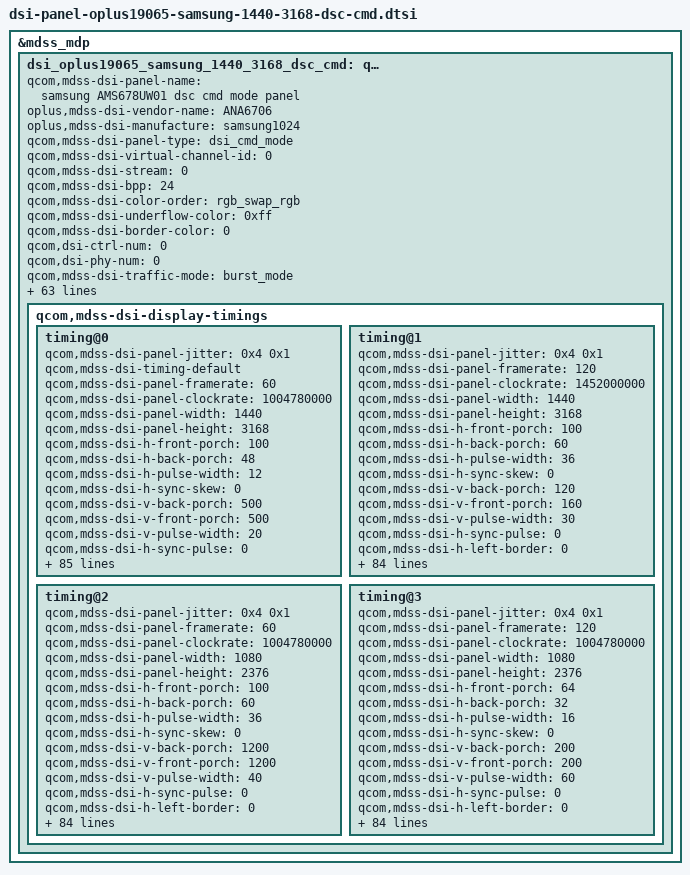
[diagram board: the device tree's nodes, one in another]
&mdss_mdp {
	dsi_oplus19065_samsung_1440_3168_dsc_cmd: qcom,mdss_dsi_oppo19065_samsung_1440_3168_dsc_cmd {
		qcom,mdss-dsi-panel-name = "samsung AMS678UW01 dsc cmd mode panel";
		oplus,mdss-dsi-vendor-name = "ANA6706";
		oplus,mdss-dsi-manufacture = "samsung1024";
		qcom,mdss-dsi-panel-type = "dsi_cmd_mode";
		qcom,mdss-dsi-virtual-channel-id = <0>;
		qcom,mdss-dsi-stream = <0>;
		qcom,mdss-dsi-bpp = <24>;
		qcom,mdss-dsi-color-order = "rgb_swap_rgb";
		qcom,mdss-dsi-underflow-color = <0xff>;
		qcom,mdss-dsi-border-color = <0>;
		qcom,dsi-ctrl-num = <0>;
		qcom,dsi-phy-num = <0>;
		qcom,mdss-dsi-traffic-mode = "burst_mode";
		qcom,mdss-dsi-lane-map = "lane_map_0123";
		qcom,mdss-dsi-bllp-eof-power-mode;
		qcom,mdss-dsi-bllp-power-mode;
		qcom,mdss-dsi-lane-0-state;
		qcom,mdss-dsi-lane-1-state;
		qcom,mdss-dsi-lane-2-state;
		qcom,mdss-dsi-lane-3-state;
		qcom,mdss-dsi-dma-trigger = "trigger_sw";
		qcom,mdss-dsi-mdp-trigger = "none";
		qcom,mdss-dsi-reset-sequence = <1 10>, <0 2>, <1 10>;
		qcom,mdss-dsi-te-pin-select = <1>;
		qcom,mdss-dsi-te-dcs-command = <1>;
		qcom,mdss-pan-physical-width-dimension = <71>;
		qcom,mdss-pan-physical-height-dimension = <157>;
		qcom,mdss-dsi-init-delay-us = <1000>;
		qcom,mdss-dsi-te-check-enable;
		qcom,mdss-dsi-te-using-te-pin;
		qcom,mdss-dsi-lp11-init;
		qcom,mdss-dsi-wr-mem-start = <0x2c>;
		qcom,mdss-dsi-wr-mem-continue = <0x3c>;
		/* HDR Setting */
		qcom,mdss-dsi-panel-hdr-enabled;
		qcom,mdss-dsi-panel-hdr-color-primaries = <15635 16450 34000 16000 13250 34500 7500 3000>;
		qcom,mdss-dsi-panel-peak-brightness = <5400000>;
		qcom,mdss-dsi-panel-average-brightness = <2000000>;
		qcom,mdss-dsi-panel-blackness-level = <2000>;

		qcom,esd-check-enabled;
		qcom,mdss-dsi-panel-status-check-mode = "reg_read";
		qcom,mdss-dsi-panel-status-command = [
						06 01 00 01 05 00 02 E9 00
						06 01 00 01 05 00 02 EE 00
						06 01 00 01 05 00 02 0A 00
						];
		qcom,mdss-dsi-panel-status-command-state = "dsi_hs_mode";
		qcom,mdss-dsi-panel-status-value = <0x00 0x00 0x00 0x00 0x00 0x9C>;
		qcom,mdss-dsi-panel-status-read-length = <4 1 1>;

		qcom,dynamic-mode-switch-enabled;
		qcom,dynamic-mode-switch-type = "dynamic-resolution-switch-immediate";
		qcom,mdss-dsi-display-timings {
			timing@0{
				qcom,mdss-dsi-panel-jitter = <0x4 0x1>;
				qcom,mdss-dsi-timing-default;
				qcom,mdss-dsi-panel-framerate = <60>;
				qcom,mdss-dsi-panel-clockrate = <1004780000>;
				qcom,mdss-dsi-panel-width = <1440>;
				qcom,mdss-dsi-panel-height = <3168>;

				qcom,mdss-dsi-h-front-porch = <100>;
				qcom,mdss-dsi-h-back-porch = <48>;
				qcom,mdss-dsi-h-pulse-width = <12>;
				qcom,mdss-dsi-h-sync-skew = <0>;
				qcom,mdss-dsi-v-back-porch = <500>;
				qcom,mdss-dsi-v-front-porch = <500>;
				qcom,mdss-dsi-v-pulse-width = <20>;
				qcom,mdss-dsi-h-sync-pulse = <0>;

				qcom,mdss-dsi-h-left-border = <0>;
				qcom,mdss-dsi-h-right-border = <0>;
				qcom,mdss-dsi-v-top-border = <0>;
				qcom,mdss-dsi-v-bottom-border = <0>;

				qcom,dsi-select-clocks = "mux_byte_clk0", "mux_pixel_clk0","pw_bb_clk2";

				oplus,fod-on-vblank = <1>;
				oplus,fod-off-vblank = <0>;
				qcom,mdss-dsi-panel-read-register-open-command = [
					39 01 00 00 00 00 03 F0 5A 5A
					];
				qcom,mdss-dsi-panel-id1-command = [
					06 01 00 00 00 00 01 E9
					];
				qcom,mdss-dsi-panel-read-register-close-command = [
					39 01 00 00 00 00 03 F0 A5 A5
					];
				qcom,mdss-dsi-timing-switch-command = [
					39 01 00 00 00 00 03 F0 5A 5A
					39 01 00 00 00 00 05 2A 00 00 05 9F 		/* CASET */
					39 01 00 00 00 00 05 2B 00 00 0C 5F 		/* PASET */
					15 01 00 00 00 00 02 60 00					/* 60HZ */
					15 01 00 00 00 00 02 F7 0F
					15 01 00 00 00 00 02 BA 03
					39 01 00 00 07 00 03 F0 A5 A5
				];
				qcom,mdss-dsi-on-command = [
					/* Sleep Out(11h) */
					05 01 00 00 0B 00 01 11
					/* SP Error improvement Setting*/
					39 01 00 00 00 00 03 F0 5A 5A
					15 01 00 00 00 00 02 B0 4F
					39 01 00 00 00 00 03 F5 5C 78
					15 01 00 00 00 00 02 B0 07
					15 01 00 00 00 00 02 C0 68
					39 01 00 00 00 00 03 F0 A5 A5
					/* color dot improment */
					39 01 00 00 00 00 03 F0 5A 5A
					15 01 00 00 00 00 02 B0 22
					15 01 00 00 00 00 02 F5 65
					15 01 00 00 00 00 02 B0 38
					15 01 00 00 00 00 02 F5 0F
					15 01 00 00 00 00 02 B0 56
					15 01 00 00 00 00 02 F5 C4
					39 01 00 00 00 00 03 F0 A5 A5
					/* Green Line improvement Setting */
					39 01 00 00 00 00 03 F0 5A 5A
					15 01 00 00 00 00 02 B0 03
					39 01 00 00 00 00 03 CB FF FF
					15 01 00 00 00 00 02 F7 0F
					39 01 00 00 0B 00 03 F0 A5 A5
					/* DSC Setting */
					07 01 00 00 00 00 01 01
					/* DSC enable */
					39 01 00 00 00 00 59 9E
					11 00 00 AB 30 A0 0C 60
					05 A0 00 10 02 D0 03 84
					01 9A 02 68 00 19 01 d1
					00 0E 00 09 04 cd 05 d6
					16 00 10 EC 07 10 20 00
					06 0F 0F 33 0E 1C 2A 38
					46 54 62 69 70 77 79 7B
					7D 7E 02 02 22 00 2A 40
					32 BE 3A FC 3A FA 3A F8
					3B 38 3B 78 3B 76 4B B6
					4B B4 4B F4 5B F4 7C 34
					39 01 00 00 00 00 03 F0 5A 5A
					15 01 00 00 00 00 02 F7 0F
					39 01 00 00 00 00 03 F0 A5 A5
					/* Common Setting */
					15 01 00 00 00 00 02 35 00					/* TE On(Vsync) */
					/* CASET/PASET Setting */
					39 01 00 00 00 00 05 2A 00 00 05 9F 		/* CASET */
					39 01 00 00 00 00 05 2B 00 00 0C 5F 		/* PASET */
					/* TSP SYNC Setting */
					39 01 00 00 00 00 03 F0 5A 5A
					15 01 00 00 00 00 02 B0 05
					39 01 00 00 00 00 05 B9 07 02 40 23 		/* SYNC ENABLE */
					39 01 00 00 00 00 03 F0 A5 A5
					/* FD Setting On */
					39 01 00 00 00 00 03 F0 5A 5A
					15 01 00 00 00 00 02 B0 54
					15 01 00 00 00 00 02 B5 48
					39 01 00 00 6F 00 03 F0 A5 A5
					/* Brightness Control */
					39 01 00 00 00 00 03 F0 5A 5A				/* Dimming Setting */
					15 01 00 00 00 00 02 B0 0B
					15 01 00 00 00 00 02 B1 01					/* Dimming Speed Setting : 0x01 : 1Frame*/
					15 01 00 00 00 00 02 B0 02
					15 01 00 00 00 00 02 B5 13					/* 0x13 : ELVSS DIM OFF */
					15 01 00 00 00 00 02 53 28
					39 01 00 00 00 00 03 F0 A5 A5
					/* 60Hz */
					39 01 00 00 00 00 03 F0 5A 5A
					15 01 00 00 00 00 02 60 00					/*60HZ*/
					15 01 00 00 00 00 02 F7 0F
					15 01 00 00 00 00 02 BA 03
					39 01 00 00 00 00 03 F0 A5 A5
				];
				qcom,mdss-dsi-post-on-backlight = [
					/* Display On */
					39 01 00 00 00 00 03 9F 5A 5A
					05 01 00 00 00 00 01 29
					05 01 00 00 00 00 01 13
					39 01 00 00 00 00 03 9F A5 A5
				];
				qcom,mdss-dsi-off-command=[
					05 01 00 00 0A 00 02 28 00
					05 01 00 00 78 00 02 10 00
				];
				qcom,mdss-dsi-lp1-command = [
					/* SEED CRC OFF */
					15 01 00 00 00 00 02 82 00
					/* Aod Mode */
					39 01 00 00 00 00 03 F0 5A 5A
					15 01 00 00 00 00 02 B0 06
					15 01 00 00 00 00 02 F4 8A
					15 01 00 00 00 00 02 BB 29
					15 01 00 00 00 00 02 6A 00
					15 01 00 00 00 00 02 53 22
					39 01 00 00 14 00 03 F0 A5 A5
				];
				qcom,mdss-dsi-nolp-command = [
					39 01 00 00 00 00 03 F0 5A 5A
					15 00 00 00 00 00 02 60 00 /*60HZ*/
					15 00 00 00 00 00 02 F7 0F
					39 01 00 00 00 00 03 F0 A5 A5
					/* Normal Mode */
					39 01 00 00 00 00 03 F0 5A 5A
					15 01 00 00 00 00 02 6A 00
					15 01 00 00 00 00 02 53 28
					39 01 00 00 00 00 03 F0 A5 A5
				];
				qcom,mdss-dsi-aod-hbm-on-command = [
					/* HBM Mode ON */
					39 01 00 00 00 00 02 53 E0
					/* 0xE0 Normal transition */
					39 01 00 00 00 00 03 51 05 93
				];
				qcom,mdss-dsi-aod-hbm-off-command = [
					15 01 00 00 00 00 02 53 22
					39 01 00 00 00 00 03 51 00 01
				];
				qcom,mdss-dsi-hbm-on-command = [
					15 01 00 00 00 00 02 53 E0
					39 01 00 00 22 00 03 51 05 93
				];
				qcom,mdss-dsi-normal-hbm-on-command = [
					15 01 00 00 00 00 02 53 E0
					39 01 00 00 00 00 03 51 07 FF
				];
				qcom,mdss-dsi-aod-high-mode-command = [
					/* AOD 50nit */
					15 01 00 00 00 00 02 53 22
				];
				qcom,mdss-dsi-aod-low-mode-command = [
					/* AOD 10nit */
					15 01 00 00 00 00 02 53 23
				];
				qcom,mdss-dsi-seed-off-command = [
					/* TCS OFF */
					39 01 00 00 00 00 03 F0 5A 5A
					15 01 00 00 00 00 02 84 00
					39 01 00 00 00 00 03 F0 A5 A5
					/* CRC OFF */
					39 01 00 00 00 00 03 F0 5A 5A
					15 01 00 00 00 00 02 B8 01
					39 01 00 00 00 00 03 F0 A5 A5
				];
				qcom,mdss-dsi-seed-0-command = [
					39 01 00 00 00 00 03 F0 5A 5A
					15 01 00 00 00 00 02 B0 0C
					15 01 00 00 00 00 02 92 07
					39 01 00 00 00 00 03 F0 A5 A5
				];
				qcom,mdss-dsi-seed-1-command = [
					39 01 00 00 00 00 03 F0 5A 5A
					15 01 00 00 00 00 02 B0 0C
					15 01 00 00 00 00 02 92 27
					39 01 00 00 00 00 03 F0 A5 A5
				];
				qcom,mdss-dsi-seed-2-command = [
					39 01 00 00 00 00 03 F0 5A 5A
					15 01 00 00 00 00 02 B0 0C
					15 01 00 00 00 00 02 92 07
					39 01 00 00 00 00 03 F0 A5 A5
				];
				qcom,mdss-dsi-mca-on-command = [
					/* MCA ON */
					39 01 00 00 00 00 03 F0 5A 5A
					15 01 00 00 00 00 02 B0 06
					15 01 00 00 00 00 02 97 01
					15 01 00 00 00 00 02 B0 04
					15 01 00 00 00 00 02 98 01
					39 01 00 00 00 00 03 F0 A5 A5
				];
				qcom,mdss-dsi-mca-off-command = [
					/* MCA OFF */
					39 01 00 00 00 00 03 F0 5A 5A
					15 01 00 00 00 00 02 B0 06
					15 01 00 00 00 00 02 97 00
					15 01 00 00 00 00 02 B0 04
					15 01 00 00 00 00 02 98 00
					39 01 00 00 00 00 03 F0 A5 A5
				];
				qcom,mdss-dsi-aod-hbm-on-command-state = "dsi_hs_mode";
				qcom,mdss-dsi-aod-hbm-off-command-state = "dsi_hs_mode";
				qcom,mdss-dsi-timing-switch-command-state = "dsi_hs_mode";
				qcom,mdss-dsi-on-command-state = "dsi_lp_mode";
				qcom,mdss-dsi-off-command-state = "dsi_hs_mode";
				qcom,mdss-dsi-seed-off-command-state = "dsi_hs_mode";
				qcom,mdss-dsi-seed-0-command-state = "dsi_hs_mode";
				qcom,mdss-dsi-seed-1-command-state = "dsi_hs_mode";
				qcom,mdss-dsi-seed-2-command-state = "dsi_hs_mode";

				qcom,compression-mode = "dsc";
				qcom,lm-split = <720 720>;
				qcom,mdss-dsc-encoders = <2>;
				qcom,mdss-dsc-slice-height = <16>;
				qcom,mdss-dsc-slice-width = <720>;
				qcom,mdss-dsc-slice-per-pkt = <2>;
				qcom,mdss-dsc-bit-per-component = <10>;
				qcom,mdss-dsc-bit-per-pixel = <10>;
				qcom,mdss-dsc-block-prediction-enable;
				qcom,mdss-dsi-panel-id1-command-state = "dsi_lp_mode";
				qcom,mdss-dsi-panel-read-register-open-state = "dsi_lp_mode";
				qcom,mdss-dsi-panel-read-register-close-state = "dsi_lp_mode";
			};
			timing@1 {
				qcom,mdss-dsi-panel-jitter = <0x4 0x1>;
				qcom,mdss-dsi-panel-framerate = <120>;
				qcom,mdss-dsi-panel-clockrate = <1452000000>;
				qcom,mdss-dsi-panel-width = <1440>;
				qcom,mdss-dsi-panel-height = <3168>;

				qcom,mdss-dsi-h-front-porch = <100>;
				qcom,mdss-dsi-h-back-porch = <60>;
				qcom,mdss-dsi-h-pulse-width = <36>;
				qcom,mdss-dsi-h-sync-skew = <0>;
				qcom,mdss-dsi-v-back-porch = <120>;
				qcom,mdss-dsi-v-front-porch = <160>;
				qcom,mdss-dsi-v-pulse-width = <30>;
				qcom,mdss-dsi-h-sync-pulse = <0>;
				qcom,mdss-dsi-h-left-border = <0>;
				qcom,mdss-dsi-h-right-border = <0>;
				qcom,mdss-dsi-v-top-border = <0>;
				qcom,mdss-dsi-v-bottom-border = <0>;

				qcom,dsi-select-clocks = "mux_byte_clk0", "mux_pixel_clk0","pw_bb_clk2";

				oplus,fod-on-vblank = <2>;
				oplus,fod-off-vblank = <0>;

				qcom,mdss-dsi-panel-read-register-open-command = [
					39 01 00 00 00 00 03 F0 5A 5A
					];
				qcom,mdss-dsi-panel-id1-command = [
					06 01 00 00 00 00 01 E9
					];
				qcom,mdss-dsi-panel-read-register-close-command = [
					39 01 00 00 00 00 03 F0 A5 A5
					];
				qcom,mdss-dsi-timing-switch-command = [
					39 01 00 00 00 00 03 F0 5A 5A
					39 01 00 00 00 00 05 2A 00 00 05 9F 		/* CASET */
					39 01 00 00 00 00 05 2B 00 00 0C 5F 		/* PASET */
					15 01 00 00 00 00 02 60 20					/* 120HZ */
					15 01 00 00 00 00 02 F7 0F
					15 01 00 00 00 00 02 BA 03
					39 01 00 00 07 00 03 F0 A5 A5
				];
				qcom,mdss-dsi-on-command = [
					/* Sleep Out(11h) */
					05 01 00 00 0B 00 01 11
					/* SP Error improvement Setting*/
					39 01 00 00 00 00 03 F0 5A 5A
					15 01 00 00 00 00 02 B0 4F
					39 01 00 00 00 00 03 F5 5C 78
					15 01 00 00 00 00 02 B0 07
					15 01 00 00 00 00 02 C0 68
					39 01 00 00 00 00 03 F0 A5 A5
					/* color dot improment */
					39 01 00 00 00 00 03 F0 5A 5A
					15 01 00 00 00 00 02 B0 22
					15 01 00 00 00 00 02 F5 65
					15 01 00 00 00 00 02 B0 38
					15 01 00 00 00 00 02 F5 0F
					15 01 00 00 00 00 02 B0 56
					15 01 00 00 00 00 02 F5 C4
					39 01 00 00 00 00 03 F0 A5 A5
					/* Green Line improvement Setting */
					39 01 00 00 00 00 03 F0 5A 5A
					15 01 00 00 00 00 02 B0 03
					39 01 00 00 00 00 03 CB FF FF
					15 01 00 00 00 00 02 F7 0F
					39 01 00 00 0B 00 03 F0 A5 A5
					/* DSC Setting */
					07 01 00 00 00 00 01 01
					/* DSC enable */
					39 01 00 00 00 00 59 9E
					12 00 00 AB 30 80 0C 60
					05 A0 00 60 02 D0 02 D0
					02 00 02 C2 00 20 09 62
					00 0A 00 0F 01 44 00 CC
					18 00 10 F0 07 10 20 00
					06 0F 0F 33 0E 1C 2A 38
					46 54 62 69 70 77 79 7B
					7D 7E 02 02 22 00 2A 40
					2A BE 3A FC 3A FA 3A F8
					3B 38 3B 78 3B B6 4B B6
					4B F4 4B F4 6C 34 84 74
					39 01 00 00 00 00 03 F0 5A 5A
					15 01 00 00 00 00 02 F7 0F
					39 01 00 00 00 00 03 F0 A5 A5
					/* Common Setting */
					15 01 00 00 00 00 02 35 00					/* TE On(Vsync) */
					/* CASET/PASET Setting */
					39 01 00 00 00 00 05 2A 00 00 05 9F 		/* CASET */
					39 01 00 00 00 00 05 2B 00 00 0C 5F 		/* PASET */
					/* TSP SYNC Setting */
					39 01 00 00 00 00 03 F0 5A 5A
					15 01 00 00 00 00 02 B0 05
					39 01 00 00 00 00 05 B9 07 02 40 23 		/* SYNC ENABLE */
					39 01 00 00 00 00 03 F0 A5 A5
					/* FD Setting On */
					39 01 00 00 00 00 03 F0 5A 5A
					15 01 00 00 00 00 02 B0 54
					15 01 00 00 00 00 02 B5 48
					39 01 00 00 6F 00 03 F0 A5 A5
					/* Brightness Control */
					39 01 00 00 00 00 03 F0 5A 5A				/* Dimming Setting */
					15 01 00 00 00 00 02 B0 0B
					15 01 00 00 00 00 02 B1 01					/* Dimming Speed Setting : 0x01 : 1Frame*/
					15 01 00 00 00 00 02 B0 02
					15 01 00 00 00 00 02 B5 13					/* 0x13 : ELVSS DIM OFF */
					15 01 00 00 00 00 02 53 28
					39 01 00 00 00 00 03 F0 A5 A5
					/* 120HZ */
					39 01 00 00 00 00 03 F0 5A 5A
					15 01 00 00 00 00 02 60 20					/* 120HZ */
					15 01 00 00 00 00 02 F7 0F
					15 01 00 00 00 00 02 BA 03
					39 01 00 00 00 00 03 F0 A5 A5
				];
				qcom,mdss-dsi-post-on-backlight = [
					/* Display On */
					39 01 00 00 00 00 03 9F 5A 5A
					05 01 00 00 00 00 01 29
					05 01 00 00 00 00 01 13
					39 01 00 00 00 00 03 9F A5 A5
				];
				qcom,mdss-dsi-off-command=[
					05 01 00 00 0A 00 02 28 00
					05 01 00 00 78 00 02 10 00
				];
				qcom,mdss-dsi-lp1-command = [
					/* SEED CRC OFF */
					15 01 00 00 00 00 02 82 00
					/* Aod Mode */
					39 01 00 00 00 00 03 F0 5A 5A
					15 01 00 00 00 00 02 B0 06
					15 01 00 00 00 00 02 F4 8A
					15 01 00 00 00 00 02 BB 29
					15 01 00 00 00 00 02 6A 00
					15 01 00 00 00 00 02 53 22
					39 01 00 00 14 00 03 F0 A5 A5
				];
				qcom,mdss-dsi-nolp-command = [
					39 01 00 00 00 00 03 F0 5A 5A
					15 00 00 00 00 00 02 60 20 /*120HZ*/
					15 00 00 00 00 00 02 F7 0F
					39 01 00 00 00 00 03 F0 A5 A5
					/* Normal Mode */
					39 01 00 00 00 00 03 F0 5A 5A
					15 01 00 00 00 00 02 6A 00
					15 01 00 00 00 00 02 53 28
					39 01 00 00 00 00 03 F0 A5 A5
				];
				qcom,mdss-dsi-aod-hbm-on-command = [
					/* HBM Mode ON */
					39 01 00 00 00 00 02 53 E0
					/* 0xE0 Normal transition */
					39 01 00 00 00 00 03 51 05 93
				];
				qcom,mdss-dsi-aod-hbm-off-command = [
					15 01 00 00 00 00 02 53 22
					39 01 00 00 00 00 03 51 00 01
				];
				qcom,mdss-dsi-hbm-on-command = [
					15 01 00 00 00 00 02 53 E0
					39 01 00 00 22 00 03 51 05 93
				];
				qcom,mdss-dsi-normal-hbm-on-command = [
					15 01 00 00 00 00 02 53 E0
					39 01 00 00 00 00 03 51 07 FF
				];
				qcom,mdss-dsi-aod-high-mode-command = [
					/* AOD 50nit */
					15 01 00 00 00 00 02 53 22
				];
				qcom,mdss-dsi-aod-low-mode-command = [
					/* AOD 10nit */
					15 01 00 00 00 00 02 53 23
				];
				qcom,mdss-dsi-seed-off-command = [
					/* TCS OFF */
					39 01 00 00 00 00 03 F0 5A 5A
					15 01 00 00 00 00 02 84 00
					39 01 00 00 00 00 03 F0 A5 A5
					/* CRC OFF */
					39 01 00 00 00 00 03 F0 5A 5A
					15 01 00 00 00 00 02 B8 01
					39 01 00 00 00 00 03 F0 A5 A5
				];
				qcom,mdss-dsi-seed-0-command = [
					39 01 00 00 00 00 03 F0 5A 5A
					15 01 00 00 00 00 02 B0 0C
					15 01 00 00 00 00 02 92 07
					39 01 00 00 00 00 03 F0 A5 A5
				];
				qcom,mdss-dsi-seed-1-command = [
					39 01 00 00 00 00 03 F0 5A 5A
					15 01 00 00 00 00 02 B0 0C
					15 01 00 00 00 00 02 92 27
					39 01 00 00 00 00 03 F0 A5 A5
				];
				qcom,mdss-dsi-seed-2-command = [
					39 01 00 00 00 00 03 F0 5A 5A
					15 01 00 00 00 00 02 B0 0C
					15 01 00 00 00 00 02 92 07
					39 01 00 00 00 00 03 F0 A5 A5
				];
				qcom,mdss-dsi-mca-on-command = [
					/* MCA ON */
					39 01 00 00 00 00 03 F0 5A 5A
					15 01 00 00 00 00 02 B0 06
					15 01 00 00 00 00 02 97 01
					15 01 00 00 00 00 02 B0 04
					15 01 00 00 00 00 02 98 01
					39 01 00 00 00 00 03 F0 A5 A5
				];
				qcom,mdss-dsi-mca-off-command = [
					/* MCA OFF */
					39 01 00 00 00 00 03 F0 5A 5A
					15 01 00 00 00 00 02 B0 06
					15 01 00 00 00 00 02 97 00
					15 01 00 00 00 00 02 B0 04
					15 01 00 00 00 00 02 98 00
					39 01 00 00 00 00 03 F0 A5 A5
				];
				qcom,mdss-dsi-aod-hbm-on-command-state = "dsi_hs_mode";
				qcom,mdss-dsi-aod-hbm-off-command-state = "dsi_hs_mode";
				qcom,mdss-dsi-timing-switch-command-state = "dsi_hs_mode";
				qcom,mdss-dsi-on-command-state = "dsi_lp_mode";
				qcom,mdss-dsi-off-command-state = "dsi_hs_mode";
				qcom,mdss-dsi-seed-off-command-state = "dsi_hs_mode";
				qcom,mdss-dsi-seed-0-command-state = "dsi_hs_mode";
				qcom,mdss-dsi-seed-1-command-state = "dsi_hs_mode";
				qcom,mdss-dsi-seed-2-command-state = "dsi_hs_mode";

				qcom,compression-mode = "dsc";
				qcom,lm-split = <720 720>;
				qcom,mdss-dsc-encoders = <2>;
				qcom,mdss-dsc-slice-height = <96>;
				qcom,mdss-dsc-slice-width = <720>;
				qcom,mdss-dsc-slice-per-pkt = <2>;
				qcom,mdss-dsc-bit-per-component = <10>;
				qcom,mdss-dsc-bit-per-pixel = <8>;
				qcom,mdss-dsc-block-prediction-enable;
				qcom,mdss-dsi-panel-id1-command-state = "dsi_lp_mode";
				qcom,mdss-dsi-panel-read-register-open-state = "dsi_lp_mode";
				qcom,mdss-dsi-panel-read-register-close-state = "dsi_lp_mode";
			};
			timing@2 {
				qcom,mdss-dsi-panel-jitter = <0x4 0x1>;
				qcom,mdss-dsi-panel-framerate = <60>;
				qcom,mdss-dsi-panel-clockrate = <1004780000>;
				qcom,mdss-dsi-panel-width = <1080>;
				qcom,mdss-dsi-panel-height = <2376>;

				qcom,mdss-dsi-h-front-porch = <100>;
				qcom,mdss-dsi-h-back-porch = <60>;
				qcom,mdss-dsi-h-pulse-width = <36>;
				qcom,mdss-dsi-h-sync-skew = <0>;
				qcom,mdss-dsi-v-back-porch = <1200>;
				qcom,mdss-dsi-v-front-porch = <1200>;
				qcom,mdss-dsi-v-pulse-width = <40>;
				qcom,mdss-dsi-h-sync-pulse = <0>;
				qcom,mdss-dsi-h-left-border = <0>;
				qcom,mdss-dsi-h-right-border = <0>;
				qcom,mdss-dsi-v-top-border = <0>;
				qcom,mdss-dsi-v-bottom-border = <0>;

				qcom,dsi-select-clocks = "mux_byte_clk0", "mux_pixel_clk0","pw_bb_clk2";

				oplus,fod-on-vblank = <1>;
				oplus,fod-off-vblank = <0>;

				qcom,mdss-dsi-panel-read-register-open-command = [
					39 01 00 00 00 00 03 F0 5A 5A
					];
				qcom,mdss-dsi-panel-id1-command = [
					06 01 00 00 00 00 01 E9
					];
				qcom,mdss-dsi-panel-read-register-close-command = [
					39 01 00 00 00 00 03 F0 A5 A5
					];
				qcom,mdss-dsi-timing-switch-command = [
					39 01 00 00 00 00 03 F0 5A 5A
					39 01 00 00 00 00 05 2A 00 00 04 37			/* CASET */
					39 01 00 00 00 00 05 2B 00 00 09 47			/* PASET */
					15 01 00 00 00 00 02 60 02					/* 60HZ */
					15 01 00 00 00 00 02 F7 0F
					15 01 00 00 00 00 02 BA 02
					39 01 00 00 07 00 03 F0 A5 A5
				];
				qcom,mdss-dsi-on-command = [
					/* Sleep Out(11h) */
					05 01 00 00 0B 00 01 11
					/* SP Error improvement Setting*/
					39 01 00 00 00 00 03 F0 5A 5A
					15 01 00 00 00 00 02 B0 4F
					39 01 00 00 00 00 03 F5 5C 78
					15 01 00 00 00 00 02 B0 07
					15 01 00 00 00 00 02 C0 68
					39 01 00 00 00 00 03 F0 A5 A5
					/* color dot improment */
					39 01 00 00 00 00 03 F0 5A 5A
					15 01 00 00 00 00 02 B0 22
					15 01 00 00 00 00 02 F5 65
					15 01 00 00 00 00 02 B0 38
					15 01 00 00 00 00 02 F5 0F
					15 01 00 00 00 00 02 B0 56
					15 01 00 00 00 00 02 F5 C4
					39 01 00 00 00 00 03 F0 A5 A5
					/* Green Line improvement Setting */
					39 01 00 00 00 00 03 F0 5A 5A
					15 01 00 00 00 00 02 B0 03
					39 01 00 00 00 00 03 CB FF FF
					15 01 00 00 00 00 02 F7 0F
					39 01 00 00 0B 00 03 F0 A5 A5
					/* DSC Setting */
					07 01 00 00 00 00 01 01
					/* DSC enable */
					39 01 00 00 00 00 59 9E
					11 00 00 89 30 80 09 48
					04 38 00 48 02 1C 02 1C
					02 00 02 52 00 20 06 3B
					00 07 00 0F 01 B1 01 6A
					18 00 10 F0 03 0C 20 00
					06 0B 0B 33 0E 1C 2A 38
					46 54 62 69 70 77 79 7B
					7D 7E 01 02 01 00 09 40
					09 BE 19 FC 19 FA 19 F8
					1A 38 1A 78 1A B6 2A B6
					2A F4 2A F4 4B 34 63 74
					39 01 00 00 00 00 03 F0 5A 5A
					15 01 00 00 00 00 02 F7 0F
					39 01 00 00 00 00 03 F0 A5 A5
					/* Common Setting */
					15 01 00 00 00 00 02 35 00					/* TE On(Vsync) */
					/* CASET/PASET Setting */
					39 01 00 00 00 00 05 2A 00 00 04 37			/* CASET */
					39 01 00 00 00 00 05 2B 00 00 09 47			/* PASET */
					/* TSP SYNC Setting */
					39 01 00 00 00 00 03 F0 5A 5A
					15 01 00 00 00 00 02 B0 05
					39 01 00 00 00 00 05 B9 07 02 40 23			/* SYNC ENABLE */
					39 01 00 00 00 00 03 F0 A5 A5
					/* FD Setting On */
					39 01 00 00 00 00 03 F0 5A 5A
					15 01 00 00 00 00 02 B0 54
					15 01 00 00 00 00 02 B5 48
					39 01 00 00 6F 00 03 F0 A5 A5
					/* Brightness Control */
					39 01 00 00 00 00 03 F0 5A 5A				/* Dimming Setting */
					15 01 00 00 00 00 02 B0 0B
					15 01 00 00 00 00 02 B1 01					/* Dimming Speed Setting : 0x01 : 1Frame*/
					15 01 00 00 00 00 02 B0 02
					15 01 00 00 00 00 02 B5 13					/* 0x13 : ELVSS DIM OFF */
					15 01 00 00 00 00 02 53 28
					39 01 00 00 00 00 03 F0 A5 A5
					/* 60HZ */
					39 01 00 00 00 00 03 F0 5A 5A
					15 01 00 00 00 00 02 60 02					/* 60HZ */
					15 01 00 00 00 00 02 F7 0F
					15 01 00 00 00 00 02 BA 02
					39 01 00 00 00 00 03 F0 A5 A5
				];
				qcom,mdss-dsi-post-on-backlight = [
					/* Display On */
					39 01 00 00 00 00 03 9F 5A 5A
					05 01 00 00 00 00 01 29
					05 01 00 00 00 00 01 13
					39 01 00 00 00 00 03 9F A5 A5
				];
				qcom,mdss-dsi-off-command=[
					05 01 00 00 0A 00 02 28 00
					05 01 00 00 78 00 02 10 00
				];
				qcom,mdss-dsi-lp1-command = [
					/* SEED CRC OFF */
					15 01 00 00 00 00 02 82 00
					/* Aod Mode */
					39 01 00 00 00 00 03 F0 5A 5A
					15 01 00 00 00 00 02 B0 06
					15 01 00 00 00 00 02 F4 8A
					15 01 00 00 00 00 02 BB 29
					15 01 00 00 00 00 02 6A 00
					15 01 00 00 00 00 02 53 22
					39 01 00 00 14 00 03 F0 A5 A5
				];
				qcom,mdss-dsi-nolp-command = [
					39 01 00 00 00 00 03 F0 5A 5A
					15 00 00 00 00 00 02 60 02 /*60HZ*/
					15 00 00 00 00 00 02 F7 0F
					39 01 00 00 00 00 03 F0 A5 A5
					/* Normal Mode */
					39 01 00 00 00 00 03 F0 5A 5A
					15 01 00 00 00 00 02 6A 00
					15 01 00 00 00 00 02 53 28
					39 01 00 00 00 00 03 F0 A5 A5
				];
				qcom,mdss-dsi-aod-hbm-on-command = [
					/* HBM Mode ON */
					39 01 00 00 00 00 02 53 E0
					/* 0xE0 Normal transition */
					39 01 00 00 00 00 03 51 05 93
				];
				qcom,mdss-dsi-aod-hbm-off-command = [
					15 01 00 00 00 00 02 53 22
					39 01 00 00 00 00 03 51 00 01
				];
				qcom,mdss-dsi-hbm-on-command = [
					15 01 00 00 00 00 02 53 E0
					39 01 00 00 22 00 03 51 05 93
				];
				qcom,mdss-dsi-normal-hbm-on-command = [
					15 01 00 00 00 00 02 53 E0
					39 01 00 00 00 00 03 51 07 FF
				];
				qcom,mdss-dsi-aod-high-mode-command = [
					/* AOD 50nit */
					15 01 00 00 00 00 02 53 22
				];
				qcom,mdss-dsi-aod-low-mode-command = [
					/* AOD 10nit */
					15 01 00 00 00 00 02 53 23
				];
				qcom,mdss-dsi-seed-off-command = [
					/* TCS OFF */
					39 01 00 00 00 00 03 F0 5A 5A
					15 01 00 00 00 00 02 84 00
					39 01 00 00 00 00 03 F0 A5 A5
					/* CRC OFF */
					39 01 00 00 00 00 03 F0 5A 5A
					15 01 00 00 00 00 02 B8 01
					39 01 00 00 00 00 03 F0 A5 A5
				];
				qcom,mdss-dsi-seed-0-command = [
					39 01 00 00 00 00 03 F0 5A 5A
					15 01 00 00 00 00 02 B0 0C
					15 01 00 00 00 00 02 92 07
					39 01 00 00 00 00 03 F0 A5 A5
				];
				qcom,mdss-dsi-seed-1-command = [
					39 01 00 00 00 00 03 F0 5A 5A
					15 01 00 00 00 00 02 B0 0C
					15 01 00 00 00 00 02 92 27
					39 01 00 00 00 00 03 F0 A5 A5
				];
				qcom,mdss-dsi-seed-2-command = [
					39 01 00 00 00 00 03 F0 5A 5A
					15 01 00 00 00 00 02 B0 0C
					15 01 00 00 00 00 02 92 07
					39 01 00 00 00 00 03 F0 A5 A5
				];
				qcom,mdss-dsi-mca-on-command = [
					/* MCA ON */
					39 01 00 00 00 00 03 F0 5A 5A
					15 01 00 00 00 00 02 B0 06
					15 01 00 00 00 00 02 97 01
					15 01 00 00 00 00 02 B0 04
					15 01 00 00 00 00 02 98 01
					39 01 00 00 00 00 03 F0 A5 A5
				];
				qcom,mdss-dsi-mca-off-command = [
					/* MCA OFF */
					39 01 00 00 00 00 03 F0 5A 5A
					15 01 00 00 00 00 02 B0 06
					15 01 00 00 00 00 02 97 00
					15 01 00 00 00 00 02 B0 04
					15 01 00 00 00 00 02 98 00
					39 01 00 00 00 00 03 F0 A5 A5
				];
				qcom,mdss-dsi-aod-hbm-on-command-state = "dsi_hs_mode";
				qcom,mdss-dsi-aod-hbm-off-command-state = "dsi_hs_mode";
				qcom,mdss-dsi-timing-switch-command-state = "dsi_hs_mode";
				qcom,mdss-dsi-on-command-state = "dsi_lp_mode";
				qcom,mdss-dsi-off-command-state = "dsi_hs_mode";
				qcom,mdss-dsi-seed-off-command-state = "dsi_hs_mode";
				qcom,mdss-dsi-seed-0-command-state = "dsi_hs_mode";
				qcom,mdss-dsi-seed-1-command-state = "dsi_hs_mode";
				qcom,mdss-dsi-seed-2-command-state = "dsi_hs_mode";

				qcom,compression-mode = "dsc";
				qcom,lm-split = <540 540>;
				qcom,mdss-dsc-encoders = <2>;
				qcom,mdss-dsc-slice-height = <72>;
				qcom,mdss-dsc-slice-width = <540>;
				qcom,mdss-dsc-slice-per-pkt = <2>;
				qcom,mdss-dsc-bit-per-component = <8>;
				qcom,mdss-dsc-bit-per-pixel = <8>;
				qcom,mdss-dsc-block-prediction-enable;
				qcom,mdss-dsi-panel-id1-command-state = "dsi_lp_mode";
				qcom,mdss-dsi-panel-read-register-open-state = "dsi_lp_mode";
				qcom,mdss-dsi-panel-read-register-close-state = "dsi_lp_mode";
			};
			timing@3 {
				qcom,mdss-dsi-panel-jitter = <0x4 0x1>;
				qcom,mdss-dsi-panel-framerate = <120>;
				qcom,mdss-dsi-panel-clockrate = <1004780000>;
				qcom,mdss-dsi-panel-width = <1080>;
				qcom,mdss-dsi-panel-height = <2376>;

				qcom,mdss-dsi-h-front-porch = <64>;
				qcom,mdss-dsi-h-back-porch = <32>;
				qcom,mdss-dsi-h-pulse-width = <16>;
				qcom,mdss-dsi-h-sync-skew = <0>;
				qcom,mdss-dsi-v-back-porch = <200>;
				qcom,mdss-dsi-v-front-porch = <200>;
				qcom,mdss-dsi-v-pulse-width = <60>;
				qcom,mdss-dsi-h-sync-pulse = <0>;
				qcom,mdss-dsi-h-left-border = <0>;
				qcom,mdss-dsi-h-right-border = <0>;
				qcom,mdss-dsi-v-top-border = <0>;
				qcom,mdss-dsi-v-bottom-border = <0>;

				qcom,dsi-select-clocks = "mux_byte_clk0", "mux_pixel_clk0","pw_bb_clk2";

				oplus,fod-on-vblank = <2>;
				oplus,fod-off-vblank = <0>;

				qcom,mdss-dsi-panel-read-register-open-command = [
					39 01 00 00 00 00 03 F0 5A 5A
					];
				qcom,mdss-dsi-panel-id1-command = [
					06 01 00 00 00 00 01 E9
					];
				qcom,mdss-dsi-panel-read-register-close-command = [
					39 01 00 00 00 00 03 F0 A5 A5
					];
				qcom,mdss-dsi-timing-switch-command = [
					39 01 00 00 00 00 03 F0 5A 5A
					39 01 00 00 00 00 05 2A 00 00 04 37 		/* CASET */
					39 01 00 00 00 00 05 2B 00 00 09 47 		/* PASET */
					15 01 00 00 00 00 02 60 22					/* 120HZ */
					15 01 00 00 00 00 02 F7 0F
					15 01 00 00 00 00 02 BA 02
					/* for scanline */
					39 01 00 00 00 00 02 B9 01
					39 01 00 00 00 00 02 B0 01
					39 01 00 00 00 00 05 B9 0C 54 00 0B
					39 01 00 00 07 00 03 F0 A5 A5
				];
				qcom,mdss-dsi-on-command = [
					/* Sleep Out(11h) */
					05 01 00 00 0B 00 01 11
					/* SP Error improvement Setting*/
					39 01 00 00 00 00 03 F0 5A 5A
					15 01 00 00 00 00 02 B0 4F
					39 01 00 00 00 00 03 F5 5C 78
					15 01 00 00 00 00 02 B0 07
					15 01 00 00 00 00 02 C0 68
					39 01 00 00 00 00 03 F0 A5 A5
					/* color dot improment */
					39 01 00 00 00 00 03 F0 5A 5A
					15 01 00 00 00 00 02 B0 22
					15 01 00 00 00 00 02 F5 65
					15 01 00 00 00 00 02 B0 38
					15 01 00 00 00 00 02 F5 0F
					15 01 00 00 00 00 02 B0 56
					15 01 00 00 00 00 02 F5 C4
					39 01 00 00 00 00 03 F0 A5 A5
					/* Green Line improvement Setting */
					39 01 00 00 00 00 03 F0 5A 5A
					15 01 00 00 00 00 02 B0 03
					39 01 00 00 00 00 03 CB FF FF
					15 01 00 00 00 00 02 F7 0F
					39 01 00 00 0B 00 03 F0 A5 A5
					/* DSC Setting */
					07 01 00 00 00 00 01 01
					/* DSC enable */
					39 01 00 00 00 00 59 9E
					11 00 00 89 30 80 09 48
					04 38 00 48 02 1C 02 1C
					02 00 02 52 00 20 06 3B
					00 07 00 0F 01 B1 01 6A
					18 00 10 F0 03 0C 20 00
					06 0B 0B 33 0E 1C 2A 38
					46 54 62 69 70 77 79 7B
					7D 7E 01 02 01 00 09 40
					09 BE 19 FC 19 FA 19 F8
					1A 38 1A 78 1A B6 2A B6
					2A F4 2A F4 4B 34 63 74
					39 01 00 00 00 00 03 F0 5A 5A
					15 01 00 00 00 00 02 F7 0F
					39 01 00 00 00 00 03 F0 A5 A5
					/* Common Setting */
					15 01 00 00 00 00 02 35 00					/* TE On(Vsync) */
					/* CASET/PASET Setting */
					39 01 00 00 00 00 05 2A 00 00 04 37 		/* CASET */
					39 01 00 00 00 00 05 2B 00 00 09 47 		/* PASET */
					/* TSP SYNC Setting */
					39 01 00 00 00 00 03 F0 5A 5A
					15 01 00 00 00 00 02 B0 05
					39 01 00 00 00 00 05 B9 07 02 40 23 		/* SYNC ENABLE */
					39 01 00 00 00 00 03 F0 A5 A5
					/* FD Setting On */
					39 01 00 00 00 00 03 F0 5A 5A
					15 01 00 00 00 00 02 B0 54
					15 01 00 00 00 00 02 B5 48
					39 01 00 00 6F 00 03 F0 A5 A5
					/* Brightness Control */
					39 01 00 00 00 00 03 F0 5A 5A				/* Dimming Setting */
					15 01 00 00 00 00 02 B0 0B
					15 01 00 00 00 00 02 B1 01					/* Dimming Speed Setting : 0x01 : 1Frame*/
					15 01 00 00 00 00 02 B0 02
					15 01 00 00 00 00 02 B5 13					/* 0x13 : ELVSS DIM OFF */
					15 01 00 00 00 00 02 53 28
					39 01 00 00 00 00 03 F0 A5 A5
					/* 120HZ */
					39 01 00 00 00 00 03 F0 5A 5A
					15 01 00 00 00 00 02 60 22					/* 120HZ */
					15 01 00 00 00 00 02 F7 0F
					15 01 00 00 00 00 02 BA 02
					/* for scanline */
					39 01 00 00 00 00 02 B9 01
					39 01 00 00 00 00 02 B0 01
					39 01 00 00 00 00 05 B9 0C 54 00 0B
					39 01 00 00 00 00 03 F0 A5 A5
				];
				qcom,mdss-dsi-post-on-backlight = [
					/* Display On */
					39 01 00 00 00 00 03 9F 5A 5A
					05 01 00 00 00 00 01 29
					05 01 00 00 00 00 01 13
					39 01 00 00 00 00 03 9F A5 A5
				];
				qcom,mdss-dsi-off-command=[
					05 01 00 00 0A 00 02 28 00
					05 01 00 00 78 00 02 10 00
				];
				qcom,mdss-dsi-lp1-command = [
					/* SEED CRC OFF */
					15 01 00 00 00 00 02 82 00
					/* Aod Mode */
					39 01 00 00 00 00 03 F0 5A 5A
					15 01 00 00 00 00 02 B0 06
					15 01 00 00 00 00 02 F4 8A
					15 01 00 00 00 00 02 BB 29
					15 01 00 00 00 00 02 6A 00
					15 01 00 00 00 00 02 53 22
					39 01 00 00 14 00 03 F0 A5 A5
				];
				qcom,mdss-dsi-nolp-command = [
					39 01 00 00 00 00 03 F0 5A 5A
					15 00 00 00 00 00 02 60 22 /*120HZ*/
					15 00 00 00 00 00 02 F7 0F
					39 01 00 00 00 00 03 F0 A5 A5
					/* Normal Mode */
					39 01 00 00 00 00 03 F0 5A 5A
					15 01 00 00 00 00 02 6A 00
					15 01 00 00 00 00 02 53 28
					39 01 00 00 00 00 03 F0 A5 A5
				];
				qcom,mdss-dsi-aod-hbm-on-command = [
					/* HBM Mode ON */
					39 01 00 00 00 00 02 53 E0
					/* 0xE0 Normal transition */
					39 01 00 00 00 00 03 51 05 93
				];
				qcom,mdss-dsi-aod-hbm-off-command = [
					15 01 00 00 00 00 02 53 22
					39 01 00 00 00 00 03 51 00 01
				];
				qcom,mdss-dsi-hbm-on-command = [
					15 01 00 00 00 00 02 53 E0
					39 01 00 00 22 00 03 51 05 93
				];
				qcom,mdss-dsi-normal-hbm-on-command = [
					15 01 00 00 00 00 02 53 E0
					39 01 00 00 00 00 03 51 07 FF
				];
				qcom,mdss-dsi-aod-high-mode-command = [
					/* AOD 50nit */
					15 01 00 00 00 00 02 53 22
				];
				qcom,mdss-dsi-aod-low-mode-command = [
					/* AOD 10nit */
					15 01 00 00 00 00 02 53 23
				];
				qcom,mdss-dsi-seed-off-command = [
					/* TCS OFF */
					39 01 00 00 00 00 03 F0 5A 5A
					15 01 00 00 00 00 02 84 00
					39 01 00 00 00 00 03 F0 A5 A5
					/* CRC OFF */
					39 01 00 00 00 00 03 F0 5A 5A
					15 01 00 00 00 00 02 B8 01
					39 01 00 00 00 00 03 F0 A5 A5
				];
				qcom,mdss-dsi-seed-0-command = [
					39 01 00 00 00 00 03 F0 5A 5A
					15 01 00 00 00 00 02 B0 0C
					15 01 00 00 00 00 02 92 07
					39 01 00 00 00 00 03 F0 A5 A5
				];
				qcom,mdss-dsi-seed-1-command = [
					39 01 00 00 00 00 03 F0 5A 5A
					15 01 00 00 00 00 02 B0 0C
					15 01 00 00 00 00 02 92 27
					39 01 00 00 00 00 03 F0 A5 A5
				];
				qcom,mdss-dsi-seed-2-command = [
					39 01 00 00 00 00 03 F0 5A 5A
					15 01 00 00 00 00 02 B0 0C
					15 01 00 00 00 00 02 92 07
					39 01 00 00 00 00 03 F0 A5 A5
				];
				qcom,mdss-dsi-mca-on-command = [
					/* MCA ON */
					39 01 00 00 00 00 03 F0 5A 5A
					15 01 00 00 00 00 02 B0 06
					15 01 00 00 00 00 02 97 01
					15 01 00 00 00 00 02 B0 04
					15 01 00 00 00 00 02 98 01
					39 01 00 00 00 00 03 F0 A5 A5
				];
				qcom,mdss-dsi-mca-off-command = [
					/* MCA OFF */
					39 01 00 00 00 00 03 F0 5A 5A
					15 01 00 00 00 00 02 B0 06
					15 01 00 00 00 00 02 97 00
					15 01 00 00 00 00 02 B0 04
					15 01 00 00 00 00 02 98 00
					39 01 00 00 00 00 03 F0 A5 A5
				];
				qcom,mdss-dsi-aod-hbm-on-command-state = "dsi_hs_mode";
				qcom,mdss-dsi-aod-hbm-off-command-state = "dsi_hs_mode";
				qcom,mdss-dsi-timing-switch-command-state = "dsi_hs_mode";
				qcom,mdss-dsi-on-command-state = "dsi_lp_mode";
				qcom,mdss-dsi-off-command-state = "dsi_hs_mode";
				qcom,mdss-dsi-seed-off-command-state = "dsi_hs_mode";
				qcom,mdss-dsi-seed-0-command-state = "dsi_hs_mode";
				qcom,mdss-dsi-seed-1-command-state = "dsi_hs_mode";
				qcom,mdss-dsi-seed-2-command-state = "dsi_hs_mode";

				qcom,compression-mode = "dsc";
				qcom,lm-split = <540 540>;
				qcom,mdss-dsc-encoders = <2>;
				qcom,mdss-dsc-slice-height = <72>;
				qcom,mdss-dsc-slice-width = <540>;
				qcom,mdss-dsc-slice-per-pkt = <2>;
				qcom,mdss-dsc-bit-per-component = <8>;
				qcom,mdss-dsc-bit-per-pixel = <8>;
				qcom,mdss-dsc-block-prediction-enable;
				qcom,mdss-dsi-panel-id1-command-state = "dsi_lp_mode";
				qcom,mdss-dsi-panel-read-register-open-state = "dsi_lp_mode";
				qcom,mdss-dsi-panel-read-register-close-state = "dsi_lp_mode";
			};
		};
	};
};

&dsi_oplus19065_samsung_1440_3168_dsc_cmd {
	qcom,panel-supply-entries = <&dsi_panel_pwr_supply>;
	qcom,mdss-dsi-bl-pmic-control-type = "bl_ctrl_dcs";
	qcom,mdss-dsi-bl-min-level = <1>;
	qcom,mdss-dsi-bl-normal-max-level = <1023>;
	qcom,mdss-dsi-bl-max-level = <2047>;
	qcom,mdss-brightness-normal-max-level = <1023>;
	qcom,mdss-brightness-max-level = <2047>;
	qcom,mdss-brightness-default-level = <400>;
	qcom,platform-te-gpio = <&tlmm 66 0>;
	qcom,platform-reset-gpio = <&tlmm 75 0>;
	qcom,platform-panel-vout-gpio = <&tlmm 8 0>;
	qcom,ulps-enabled;
	qcom,dsi-select-clocks = "mux_byte_clk0", "mux_pixel_clk0","pw_bb_clk2";

	qcom,mdss-dsi-display-timings {
		timing@0 { /* WQHD+ 60hz*/
			 qcom,mdss-dsi-panel-phy-timings = [00 22 08 09 25 23 09 09 06 02 04 00 1C 19];
			 qcom,display-topology = <1 1 1>,<2 2 1>;
			 qcom,default-topology-index = <1>;
		};
		timing@1 { /* WQHD+ 120HZ*/
			qcom,mdss-dsi-panel-phy-timings = [00 2F 0C 0C 2A 27 0C 0D 09 02 04 00 26 1B];
			qcom,display-topology = <1 1 1>,<2 2 1>;
			qcom,default-topology-index = <1>;
		};
		timing@2 { /* FHD+ 60hz*/
			qcom,mdss-dsi-panel-phy-timings = [00 22 08 09 25 23 09 09 06 02 04 00 1C 19];
			qcom,display-topology = <1 1 1>,<2 2 1>;
			qcom,default-topology-index = <1>;
		};
		timing@3 { /* FHD+ 120hz*/
			qcom,mdss-dsi-panel-phy-timings = [00 22 08 09 25 23 09 09 06 02 04 00 1C 19];
			qcom,display-topology = <1 1 1>,<2 2 1>;
			qcom,default-topology-index = <1>;
		};
	};
};

&dsi_oplus19065_samsung_1440_3168_dsc_cmd {
	qcom,platform-panel-te-esd-gpio = <&tlmm 109 0>;
};
&dsi_oplus19065_samsung_1440_3168_dsc_cmd {
	qcom,panel_voltage_vddi_name = "vddio";
	qcom,panel_voltage_vddi = <0 1650000 1800000 1950000>;
	qcom,panel_voltage_vddr_name = "vddio";
	qcom,panel_voltage_vddr = <1 1650000 1800000 1950000>;
};
